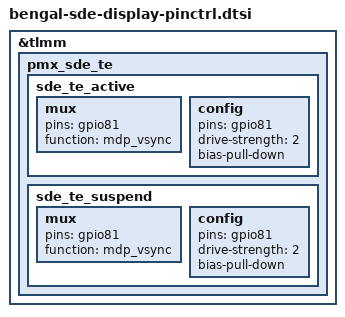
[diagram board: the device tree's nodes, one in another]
&tlmm {
	pmx_sde_te {
		sde_te_active: sde_te_active {
			mux {
				pins = "gpio81";
				function = "mdp_vsync";
			};

			config {
				pins = "gpio81";
				drive-strength = <2>;
				bias-pull-down;
			};
		};

		sde_te_suspend: sde_te_suspend {
			mux {
				pins = "gpio81";
				function = "mdp_vsync";
			};

			config {
				pins = "gpio81";
				drive-strength = <2>;
				bias-pull-down;
			};
		};
	};
};
